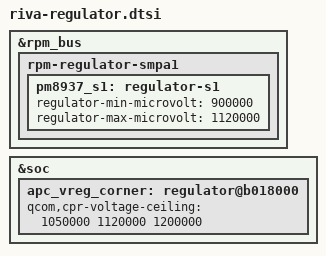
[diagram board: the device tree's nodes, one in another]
&rpm_bus {
	rpm-regulator-smpa1 {
		pm8937_s1: regulator-s1 {
			regulator-min-microvolt = <900000>;
			regulator-max-microvolt = <1120000>;
		};
	};
};

&soc {
        apc_vreg_corner: regulator@b018000 {
		qcom,cpr-voltage-ceiling = <1050000 1120000 1200000>;
	};
};
